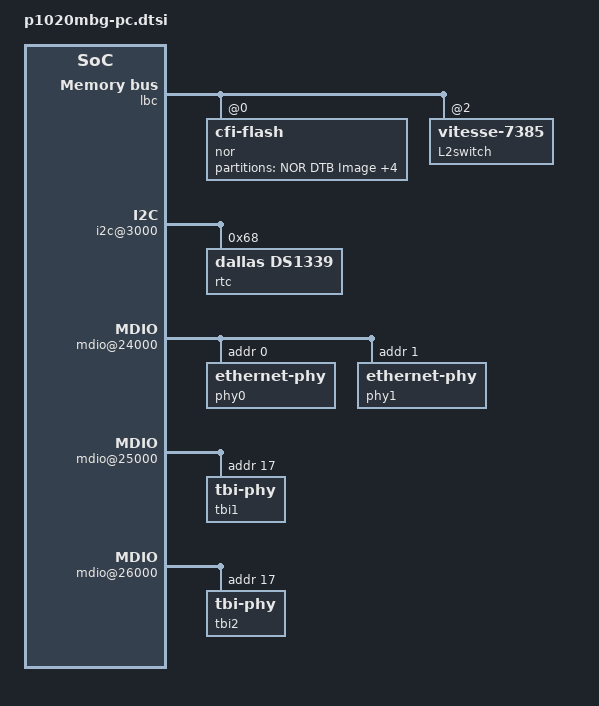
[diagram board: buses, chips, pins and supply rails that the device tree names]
&lbc {
	nor@0,0 {
		#address-cells = <1>;
		#size-cells = <1>;
		compatible = "cfi-flash";
		reg = <0x0 0x0 0x4000000>;
		bank-width = <2>;
		device-width = <1>;
		partition@0 {
			reg = <0x0 0x00020000>;
			label = "NOR DTB Image";
		};
		partition@20000 {
			reg = <0x00020000 0x003e0000>;
			label = "NOR Linux Kernel Image";
		};
		partition@400000 {
			reg = <0x00400000 0x03a00000>;
			label = "NOR Root File System";
		};
		partition@3e00000 {
			reg = <0x3e00000 0x00100000>;
			label = "NOR Vitesse-7385 Firmware";
			read-only;
		};
		partition@3f00000 {
			reg = <0x03f00000 0x00100000>;
			label = "NOR U-Boot Image";
			read-only;
		};
	};
	L2switch@2,0 {
		#address-cells = <1>;
		#size-cells = <1>;
		compatible = "vitesse-7385";
		reg = <0x2 0x0 0x20000>;
	};
};
&soc {
	i2c@3000 {
		rtc@68 {
			compatible = "dallas,ds1339";
			reg = <0x68>;
		};
	};
	mdio@24000 {
		phy0: ethernet-phy@0 {
			interrupts = <3 1 0 0>;
			reg = <0x0>;
		};
		phy1: ethernet-phy@1 {
			interrupts = <2 1 0 0>;
			reg = <0x1>;
		};
	};
	mdio@25000 {
		tbi1: tbi-phy@11 {
			reg = <0x11>;
			device_type = "tbi-phy";
		};
	};
	mdio@26000 {
		tbi2: tbi-phy@11 {
			reg = <0x11>;
			device_type = "tbi-phy";
		};
	};
	enet0: ethernet@b0000 {
		fixed-link = <1 1 1000 0 0>;
		phy-connection-type = "rgmii-id";
	};
	enet1: ethernet@b1000 {
		phy-handle = <&phy0>;
		tbi-handle = <&tbi1>;
		phy-connection-type = "sgmii";
	};
	enet2: ethernet@b2000 {
		phy-handle = <&phy1>;
		phy-connection-type = "rgmii-id";
	};
	usb@22000 {
		phy_type = "ulpi";
	};
	usb@23000 {
		status = "disabled";
		phy_type = "ulpi";
	};
};
